# MKV10Z7 register map
File version: 1.6
Registers are 32-bit, read-write, reset 0x0 unless marked. A register's access mark holds for its fields unless they carry their own. Offsets are from the block's base; [hi:lo] are bit positions; {n}, {i} and the like mark numbered series; 'fields as' and 'values as' point back to an identical list.

## FTM0 — FlexTimer Module
Base 0x40038000; register names take the prefix FTM0_
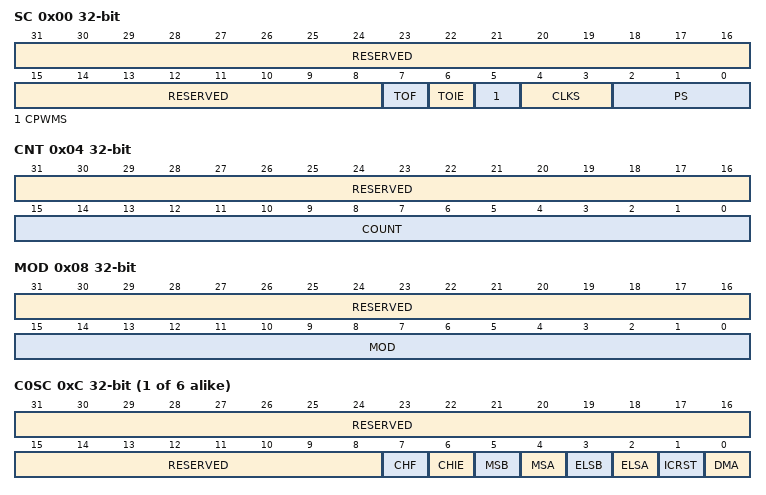
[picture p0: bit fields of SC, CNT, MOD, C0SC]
0x00 SC — Status And Control
  [31:8] RESERVED ro
  [7] TOF ro — Timer Overflow Flag
    0=FTM counter has not overflowed; 1=FTM counter has overflowed
  [6] TOIE — Timer Overflow Interrupt Enable
    0=Disable TOF interrupts. Use software polling.; 1=Enable TOF interrupts. An interrupt is generated when TOF equals one.
  [5] CPWMS — Center-Aligned PWM Select
    0=FTM counter operates in Up Counting mode; 1=FTM counter operates in Up-Down Counting mode
  [4:3] CLKS — Clock Source Selection
    0=No clock selected. This in effect disables the FTM counter.; 1=System clock; 2=Fixed frequency clock; 3=External clock
  [2:0] PS — Prescale Factor Selection
    0=Divide by 1; 1=Divide by 2; 2=Divide by 4; 3=Divide by 8; 4=Divide by 16; 5=Divide by 32; 6=Divide by 64; 7=Divide by 128
0x04 CNT — Counter
  [31:16] RESERVED ro
  [15:0] COUNT — Counter Value
0x08 MOD — Modulo
  [31:16] RESERVED, [15:0] MOD
{0xC+8i} C{i}SC (i=0..5) — Channel (n) Status And Control
  [31:8] RESERVED ro
  [7] CHF ro — Channel Flag
    0=No channel event has occurred; 1=A channel event has occurred
  [6] CHIE — Channel Interrupt Enable
    0=Disable channel interrupts. Use software polling.; 1=Enable channel interrupts
  [5] MSB — Channel Mode Select
  [4] MSA — Channel Mode Select
  [3] ELSB — Edge or Level Select
  [2] ELSA — Edge or Level Select
  [1] ICRST — FTM counter reset by the selected input capture event.
    0=FTM counter is not reset when the selected channel (n) input event is detected; 1=FTM counter is reset when the selected channel (n) input event is detected
  [0] DMA — DMA Enable
    0=Disable DMA transfers; 1=Enable DMA transfers
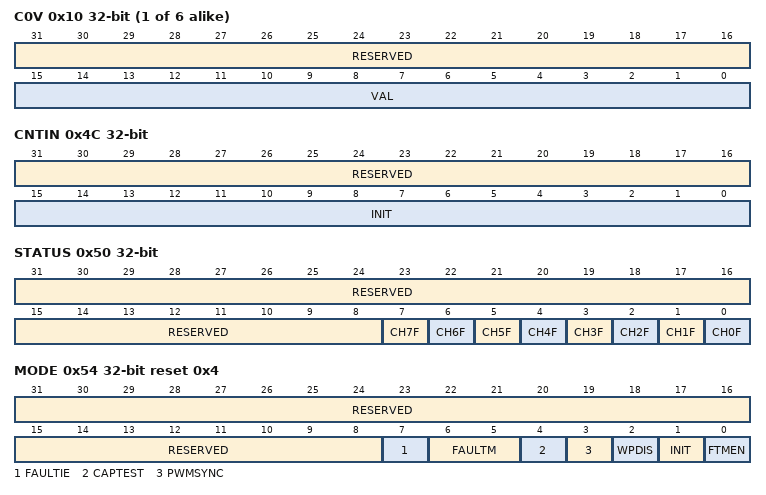
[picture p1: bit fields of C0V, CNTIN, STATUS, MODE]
{0x10+8i} C{i}V (i=0..5) — Channel (n) Value
  [31:16] RESERVED ro
  [15:0] VAL — Channel Value
0x4C CNTIN — Counter Initial Value
  [31:16] RESERVED, [15:0] INIT
0x50 STATUS ro — Capture And Compare Status
  [31:8] RESERVED
  [n] CH{n}F (n=0..7) — Channel {n} Flag
    values as C0SC.CHF
0x54 MODE reset 0x4 — Features Mode Selection
  [31:8] RESERVED ro
  [7] FAULTIE — Fault Interrupt Enable
    0=Fault control interrupt is disabled; 1=Fault control interrupt is enabled
  [6:5] FAULTM — Fault Control Mode
    0=Fault control is disabled for all channels; 1=Fault control is enabled for even channels only (channels 0, 2, 4, and 6), and the selected mode is the manual fault clearing; 2=Fault control is enabled for all channels, and the selected mode is the manual fault clearing; 3=Fault control is enabled for all channels, and the selected mode is the automatic fault clearing
  [4] CAPTEST — Capture Test Mode Enable
    0=Capture test mode is disabled; 1=Capture test mode is enabled
  [3] PWMSYNC — PWM Synchronization Mode
    0=No restrictions. Software and hardware triggers can be used by MOD, CnV, OUTMASK, and FTM counter synchronization.; 1=Software trigger can only be used by MOD and CnV synchronization, and hardware triggers can only be used by OUTMASK and FTM counter synchronization
  [2] WPDIS — Write Protection Disable
    0=Write protection is enabled; 1=Write protection is disabled
  [1] INIT — Initialize The Channels Output
  [0] FTMEN — FTM Enable
    0=Only the TPM-compatible registers (first set of registers) can be used without any restriction. Do not use the FTM-specific registers.; 1=All registers including the FTM-specific registers (second set of registers) are available for use with no restrictions
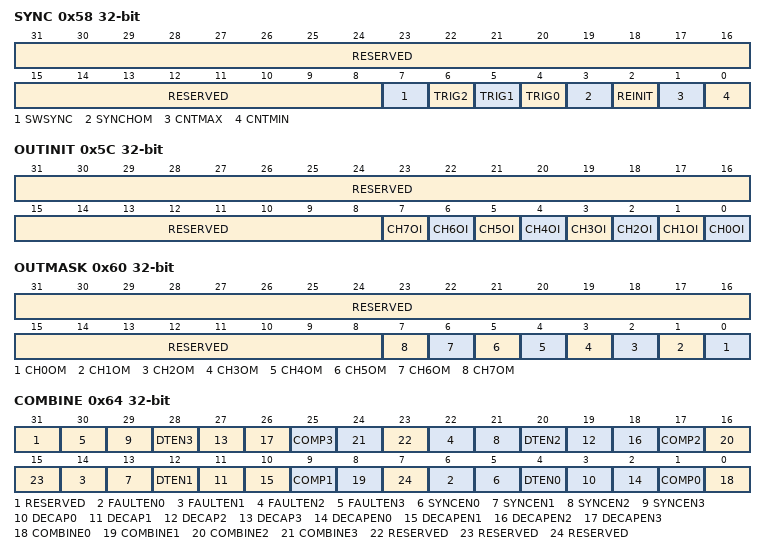
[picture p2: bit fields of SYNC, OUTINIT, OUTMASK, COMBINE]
0x58 SYNC — Synchronization
  [31:8] RESERVED ro
  [7] SWSYNC — PWM Synchronization Software Trigger
    0=Software trigger is not selected; 1=Software trigger is selected
  [6] TRIG2 — PWM Synchronization Hardware Trigger 2
    0=Trigger is disabled; 1=Trigger is enabled
  [5] TRIG1 — PWM Synchronization Hardware Trigger 1
    0=Trigger is disabled; 1=Trigger is enabled
  [4] TRIG0 — PWM Synchronization Hardware Trigger 0
    0=Trigger is disabled; 1=Trigger is enabled
  [3] SYNCHOM — Output Mask Synchronization
    0=OUTMASK register is updated with the value of its buffer in all rising edges of the system clock; 1=OUTMASK register is updated with the value of its buffer only by the PWM synchronization
  [2] REINIT — FTM Counter Reinitialization By Synchronization (FTM counter synchronization)
    0=FTM counter continues to count normally; 1=FTM counter is updated with its initial value when the selected trigger is detected
  [1] CNTMAX — Maximum Loading Point Enable
    0=The maximum loading point is disabled; 1=The maximum loading point is enabled
  [0] CNTMIN — Minimum Loading Point Enable
    0=The minimum loading point is disabled; 1=The minimum loading point is enabled
0x5C OUTINIT — Initial State For Channels Output
  [31:8] RESERVED ro
  [n] CH{n}OI (n=0..7) — Channel {n} Output Initialization Value
    0=The initialization value is 0; 1=The initialization value is 1
0x60 OUTMASK — Output Mask
  [31:8] RESERVED ro
  [n] CH{n}OM (n=0..7) — Channel {n} Output Mask
    0=Channel output is not masked. It continues to operate normally.; 1=Channel output is masked. It is forced to its inactive state.
0x64 COMBINE — Function For Linked Channels
  [31] RESERVED ro
  [8n+6] FAULTEN{n} (n=0..3) — Fault Control Enable For n = {2n}
    0=The fault control in this pair of channels is disabled; 1=The fault control in this pair of channels is enabled
  [8n+5] SYNCEN{n} (n=0..3) — Synchronization Enable For n = {2n}
    0=The PWM synchronization in this pair of channels is disabled; 1=The PWM synchronization in this pair of channels is enabled
  [8n+4] DTEN{n} (n=0..3) — Deadtime Enable For n = {2n}
    0=The deadtime insertion in this pair of channels is disabled; 1=The deadtime insertion in this pair of channels is enabled
  [8n+3] DECAP{n} (n=0..3) — Dual Edge Capture Mode Captures For n = {2n}
    0=The dual edge captures are inactive; 1=The dual edge captures are active
  [8n+2] DECAPEN{n} (n=0..3) — Dual Edge Capture Mode Enable For n = {2n}
    0=The Dual Edge Capture mode in this pair of channels is disabled; 1=The Dual Edge Capture mode in this pair of channels is enabled
  [25] COMP3 — Complement Of Channel (n) for n = 6
    0=The channel (n+1) output is the same as the channel (n) output; 1=The channel (n+1) output is the complement of the channel (n) output
  [8n] COMBINE{n} (n=0..3) — Combine Channels For n = {2n}
    0=Channels (n) and (n+1) are independent; 1=Channels (n) and (n+1) are combined
  [23] RESERVED ro
  [17] COMP2 — Complement Of Channel (n) For n = 4
    values as COMP3
  [15] RESERVED ro
  [9] COMP1 — Complement Of Channel (n) For n = 2
    values as COMP3
  [7] RESERVED ro
  [1] COMP0 — Complement Of Channel (n) For n = 0
    values as COMP3
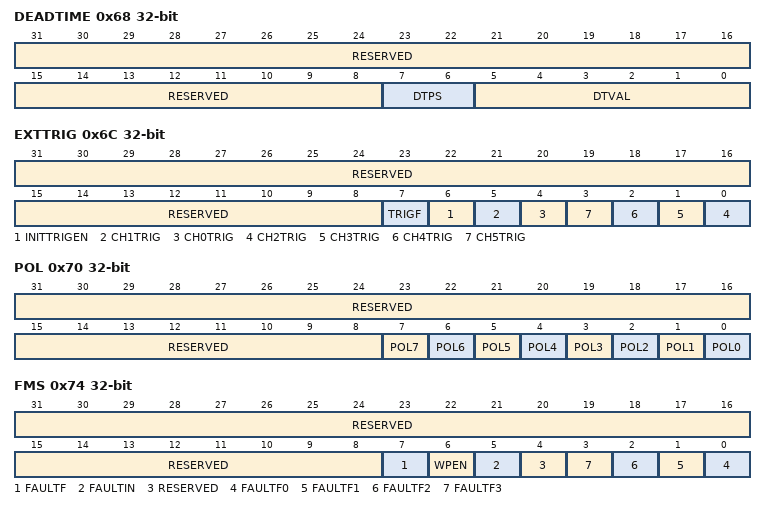
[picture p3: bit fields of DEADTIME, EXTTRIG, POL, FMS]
0x68 DEADTIME — Deadtime Insertion Control
  [31:8] RESERVED ro
  [7:6] DTPS — Deadtime Prescaler Value
    0b0x=Divide the system clock by 1; 2=Divide the system clock by 4; 3=Divide the system clock by 16
  [5:0] DTVAL — Deadtime Value
0x6C EXTTRIG — FTM External Trigger
  [31:8] RESERVED
  [7] TRIGF ro — Channel Trigger Flag
    0=No channel trigger was generated; 1=A channel trigger was generated
  [6] INITTRIGEN — Initialization Trigger Enable
    0=The generation of initialization trigger is disabled; 1=The generation of initialization trigger is enabled
  [5] CH1TRIG — Channel 1 Trigger Enable
    0=The generation of the channel trigger is disabled; 1=The generation of the channel trigger is enabled
  [4] CH0TRIG — Channel 0 Trigger Enable
    values as CH1TRIG
  [n-2] CH{n}TRIG (n=2..5) — Channel {n} Trigger Enable
    values as CH1TRIG
0x70 POL — Channels Polarity
  [31:8] RESERVED
  [n] POL{n} (n=0..7) — Channel {n} Polarity
    0=The channel polarity is active high; 1=The channel polarity is active low
0x74 FMS — Fault Mode Status
  [31:8] RESERVED ro
  [7] FAULTF ro — Fault Detection Flag
    0=No fault condition was detected; 1=A fault condition was detected
  [6] WPEN — Write Protection Enable
    0=Write protection is disabled. Write protected bits can be written.; 1=Write protection is enabled. Write protected bits cannot be written.
  [5] FAULTIN ro — Fault Inputs
    0=The logic OR of the enabled fault inputs is 0; 1=The logic OR of the enabled fault inputs is 1
  [4] RESERVED ro
  [n] FAULTF{n} ro (n=0..3) — Fault Detection Flag {n}
    0=No fault condition was detected at the fault input; 1=A fault condition was detected at the fault input
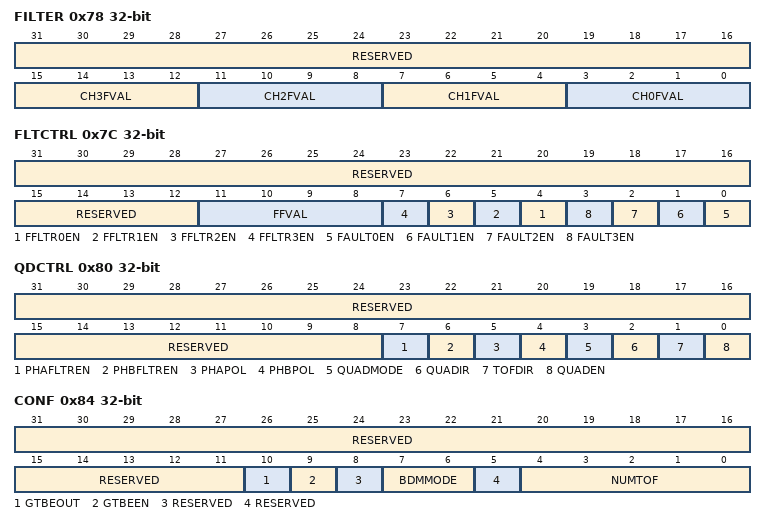
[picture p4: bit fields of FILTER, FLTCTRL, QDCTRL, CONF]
0x78 FILTER — Input Capture Filter Control
  [31:16] RESERVED
  [4n+3:4n] CH{n}FVAL (n=0..3) — Channel {n} Input Filter
0x7C FLTCTRL — Fault Control
  [31:12] RESERVED ro
  [11:8] FFVAL — Fault Input Filter
  [n+4] FFLTR{n}EN (n=0..3) — Fault Input {n} Filter Enable
    0=Fault input filter is disabled; 1=Fault input filter is enabled
  [n] FAULT{n}EN (n=0..3) — Fault Input {n} Enable
    0=Fault input is disabled; 1=Fault input is enabled
0x80 QDCTRL — Quadrature Decoder Control And Status
  [31:8] RESERVED ro
  [7] PHAFLTREN — Phase A Input Filter Enable
    0=Phase A input filter is disabled; 1=Phase A input filter is enabled
  [6] PHBFLTREN — Phase B Input Filter Enable
    0=Phase B input filter is disabled; 1=Phase B input filter is enabled
  [5] PHAPOL — Phase A Input Polarity
    0=Normal polarity. Phase A input signal is not inverted before identifying the rising and falling edges of this signal.; 1=Inverted polarity. Phase A input signal is inverted before identifying the rising and falling edges of this signal.
  [4] PHBPOL — Phase B Input Polarity
    0=Normal polarity. Phase B input signal is not inverted before identifying the rising and falling edges of this signal.; 1=Inverted polarity. Phase B input signal is inverted before identifying the rising and falling edges of this signal.
  [3] QUADMODE — Quadrature Decoder Mode
    0=Phase A and phase B encoding mode; 1=Count and direction encoding mode
  [2] QUADIR ro — FTM Counter Direction In Quadrature Decoder Mode
    0=Counting direction is decreasing (FTM counter decrement); 1=Counting direction is increasing (FTM counter increment)
  [1] TOFDIR ro — Timer Overflow Direction In Quadrature Decoder Mode
    0=TOF bit was set on the bottom of counting. There was an FTM counter decrement and FTM counter changes from its minimum value (CNTIN register) to its maximum value (MOD register).; 1=TOF bit was set on the top of counting. There was an FTM counter increment and FTM counter changes from its maximum value (MOD register) to its minimum value (CNTIN register).
  [0] QUADEN — Quadrature Decoder Mode Enable
    0=Quadrature Decoder mode is disabled; 1=Quadrature Decoder mode is enabled
0x84 CONF — Configuration
  [31:11] RESERVED ro
  [10] GTBEOUT — Global Time Base Output
    0=A global time base signal generation is disabled; 1=A global time base signal generation is enabled
  [9] GTBEEN — Global Time Base Enable
    0=Use of an external global time base is disabled; 1=Use of an external global time base is enabled
  [8] RESERVED ro
  [7:6] BDMMODE
  [5] RESERVED ro
  [4:0] NUMTOF — TOF Frequency
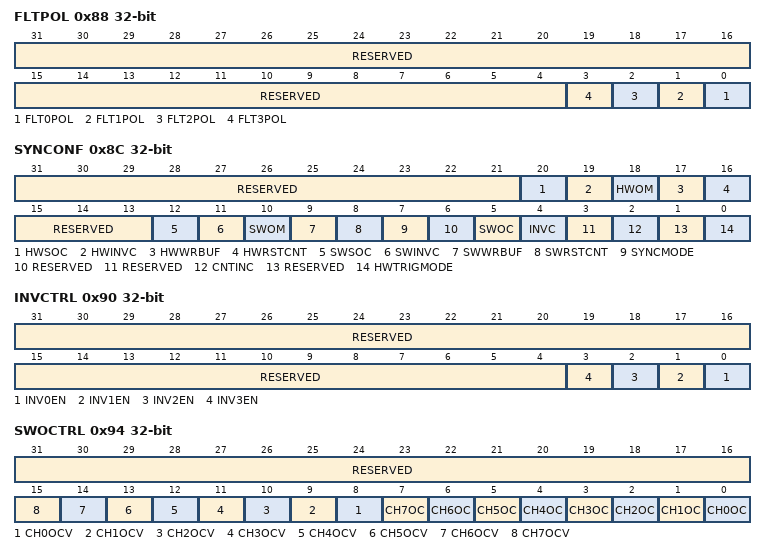
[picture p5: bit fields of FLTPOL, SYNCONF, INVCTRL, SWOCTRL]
0x88 FLTPOL — FTM Fault Input Polarity
  [31:4] RESERVED ro
  [n] FLT{n}POL (n=0..3) — Fault Input {n} Polarity
    0=The fault input polarity is active high. A one at the fault input indicates a fault.; 1=The fault input polarity is active low. A zero at the fault input indicates a fault.
0x8C SYNCONF — Synchronization Configuration
  [31:21] RESERVED ro
  [20] HWSOC
    0=A hardware trigger does not activate the SWOCTRL register synchronization; 1=A hardware trigger activates the SWOCTRL register synchronization
  [19] HWINVC
    0=A hardware trigger does not activate the INVCTRL register synchronization; 1=A hardware trigger activates the INVCTRL register synchronization
  [18] HWOM
    0=A hardware trigger does not activate the OUTMASK register synchronization; 1=A hardware trigger activates the OUTMASK register synchronization
  [17] HWWRBUF
    0=A hardware trigger does not activate MOD, CNTIN, and CV registers synchronization; 1=A hardware trigger activates MOD, CNTIN, and CV registers synchronization
  [16] HWRSTCNT
    0=A hardware trigger does not activate the FTM counter synchronization; 1=A hardware trigger activates the FTM counter synchronization
  [15:13] RESERVED ro
  [12] SWSOC
    0=The software trigger does not activate the SWOCTRL register synchronization; 1=The software trigger activates the SWOCTRL register synchronization
  [11] SWINVC
    0=The software trigger does not activate the INVCTRL register synchronization; 1=The software trigger activates the INVCTRL register synchronization
  [10] SWOM
    0=The software trigger does not activate the OUTMASK register synchronization; 1=The software trigger activates the OUTMASK register synchronization
  [9] SWWRBUF
    0=The software trigger does not activate MOD, CNTIN, and CV registers synchronization; 1=The software trigger activates MOD, CNTIN, and CV registers synchronization
  [8] SWRSTCNT
    0=The software trigger does not activate the FTM counter synchronization; 1=The software trigger activates the FTM counter synchronization
  [7] SYNCMODE — Synchronization Mode
    0=Legacy PWM synchronization is selected; 1=Enhanced PWM synchronization is selected
  [6] RESERVED ro
  [5] SWOC — SWOCTRL Register Synchronization
    0=SWOCTRL register is updated with its buffer value at all rising edges of system clock; 1=SWOCTRL register is updated with its buffer value by the PWM synchronization
  [4] INVC — INVCTRL Register Synchronization
    0=INVCTRL register is updated with its buffer value at all rising edges of system clock; 1=INVCTRL register is updated with its buffer value by the PWM synchronization
  [3] RESERVED ro
  [2] CNTINC — CNTIN Register Synchronization
    0=CNTIN register is updated with its buffer value at all rising edges of system clock; 1=CNTIN register is updated with its buffer value by the PWM synchronization
  [1] RESERVED ro
  [0] HWTRIGMODE — Hardware Trigger Mode
    0=FTM clears the TRIGj bit when the hardware trigger j is detected, where j = 0, 1,2; 1=FTM does not clear the TRIGj bit when the hardware trigger j is detected, where j = 0, 1,2
0x90 INVCTRL — FTM Inverting Control
  [31:4] RESERVED ro
  [n] INV{n}EN (n=0..3) — Pair Channels {n} Inverting Enable
    0=Inverting is disabled; 1=Inverting is enabled
0x94 SWOCTRL — FTM Software Output Control
  [31:16] RESERVED ro
  [n+8] CH{n}OCV (n=0..7) — Channel {n} Software Output Control Value
    0=The software output control forces 0 to the channel output; 1=The software output control forces 1 to the channel output
  [n] CH{n}OC (n=0..7) — Channel {n} Software Output Control Enable
    0=The channel output is not affected by software output control; 1=The channel output is affected by software output control
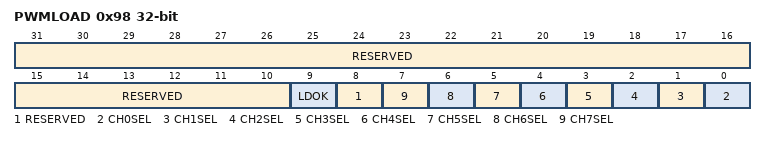
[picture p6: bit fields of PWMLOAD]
0x98 PWMLOAD — FTM PWM Load
  [31:10] RESERVED ro
  [9] LDOK — Load Enable
    0=Loading updated values is disabled; 1=Loading updated values is enabled
  [8] RESERVED ro
  [n] CH{n}SEL (n=0..7) — Channel {n} Select
    0=Do not include the channel in the matching process; 1=Include the channel in the matching process

## FTM1 — FlexTimer Module
Base 0x40039000; register names take the prefix FTM1_
Registers as FTM0, without C*SC, C*V; these are added or differ:
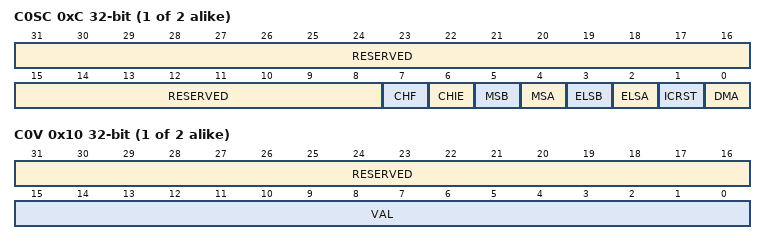
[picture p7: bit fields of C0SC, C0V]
{0xC+8i} C{i}SC (i=0..1) — Channel (n) Status And Control
  fields as FTM0.C0SC
{0x10+8i} C{i}V (i=0..1) — Channel (n) Value
  [31:16] RESERVED ro
  [15:0] VAL — Channel Value

## FTM2 — FlexTimer Module
Base 0x4003A000; register names take the prefix FTM2_
Registers as FTM1.
